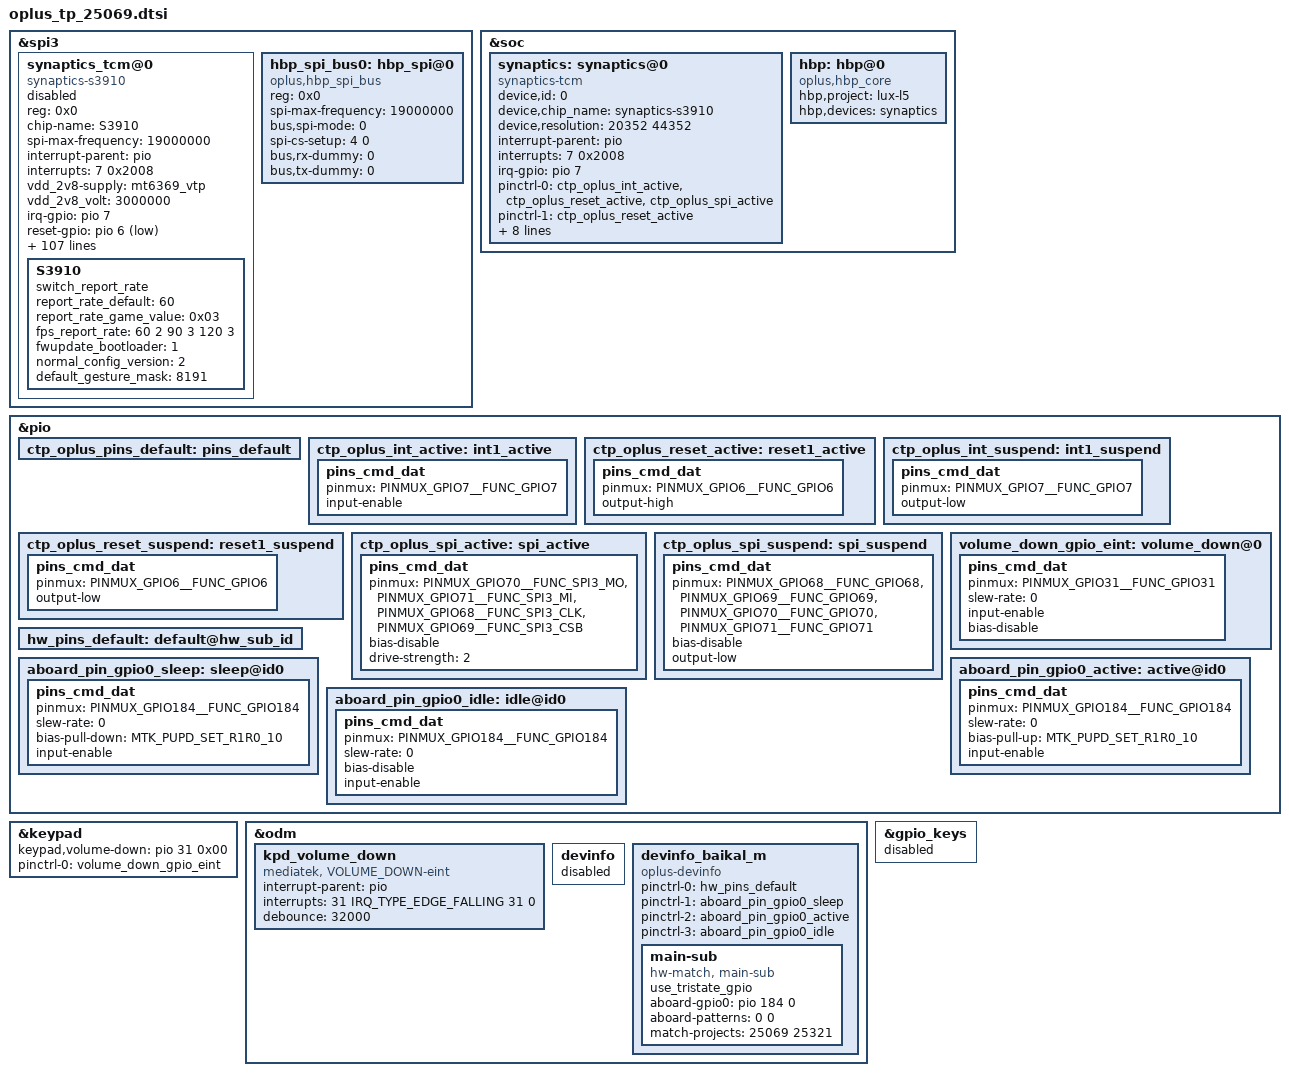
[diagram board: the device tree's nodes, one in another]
&spi3 {
	status = "okay";
	#address-cells = <1>;
	#size-cells = <0>;

	synaptics_tcm@0{
		compatible = "synaptics-s3910";
		reg = <0x0>;
		chip-name = "S3910";
		status = "disable";
		spi-max-frequency = <19000000>;

		/* Interrupt && Irq-gpio */
		interrupt-parent = <&pio>;
		interrupts = <7 0x2008>;

		/* Power Config */
		/* vcc_1v8-supply  = <&mt6369_vant18>; */
		/* vcc_1v8_volt = <1800000>; */
		vdd_2v8-supply  = <&mt6369_vtp>;
		vdd_2v8_volt = <3000000>;

		/* Other HW Resource */
		irq-gpio = <&pio 7 0x2008>;
		reset-gpio = <&pio 6 0x1>;

		pinctrl-names = "default",  "oplus_int_active",
		"oplus_reset_active", "oplus_int_suspend",
		"oplus_reset_suspend", "oplus_spi_active",
		"oplus_spi_suspend";
		pinctrl-0 = <&ctp_oplus_pins_default>;
		pinctrl-1 = <&ctp_oplus_int_active>;
		pinctrl-2 = <&ctp_oplus_reset_active>;
		pinctrl-3 = <&ctp_oplus_int_suspend>;
		pinctrl-4 = <&ctp_oplus_reset_suspend>;
		pinctrl-5 = <&ctp_oplus_spi_active>;
		pinctrl-6 = <&ctp_oplus_spi_suspend>;

		touchpanel,max-num-support = <10>;
		touchpanel,tx-rx-num = <18 39>;
		touchpanel,panel-coords = <20352 44352>;
		touchpanel,display-coords = <1272 2772>;
		touchpanel,touchmajor-limit = <128 216>;
		touchpanel,elimination-range = <20 200 200>;
		touchpanel,int-mode = <1>; /*0: interrupt and disable, 1:interrupt and not disable*/
		touchpanel,smooth-level = <0 1 2 4 7 9>;
		touchpanel,smooth-level-charging = <0 2 4 7 8 9>;
		touchpanel,sensitive-level = <0 70 55 40 25 10>;
		touchpanel,single-optimized-time = <8>;
		touchpanel,high-frame-rate-time = <60>;

		panel_type = <3 7>; /*type:7 TIANMA*/
		platform_support_project = <25069 25321>;
		platform_support_project_dir = <25069 25069>;
		platform_support_project_commandline = "ac382_p_3_a0034_vdo_panel","ac382_p_7_a0034_vdo_panel";


		prevention,curved_screen_V2;
		prevention,grip_disable_level = <6>;
		prevention,updelay_time_ms = <30>;
		prevention,makeup_cnt_weight = <4 1 2 2 2>;
		prevention,large_corner_range = <1380 3400>;
		prevention,large_corner_judge_condition = <500 300 1000 7 7>;
		prevention,trx_reject_condition = <8 7 7>;
		prevention,trx_strict_reject_condition = <8 6 6>;
		prevention,large_judge_time_ms = <500 50 30>;
		prevention,large_exit_condition = <8 8 2>;
		prevention,single_channel_width = <320 320>;
		prevention,normal_tap_condition = <10 350>;
		prevention,long_edge_condition = <179 90 120 80>;
		prevention,long_strict_edge_condition = <160 60>;
		prevention,long_fingerhold_condition = <70 6 4 4>;
		prevention,short_edge_condition = <179 90 120 80>;
		prevention,short_strict_edge_condition = <160 60>;
		prevention,large_strict_exit_condition = <6 6>;
		prevention,top_corner_config = <250 750 1000>;
		prevention,edge_swipe_config = <340 1130>;

		prevention,curved_screen_V4;
		prevention,long_eliminate_point_type = <2 20352 9240 240 44352 300 1>;
		prevention,long_fingerhold_condition2 = <700 2000 0 0>;
		prevention,top_corner_config2 =<3 80 600 1500 0>;
		prevention,hor_long_top_corner_config =<300 2000 0 0>;
		prevention,top_middle_config =<20352 1000 1000 0>;
		prevention,corner_eliminate_point_type =<0 1380 2270 1>;
		prevention,finger_hold_differ_size = <1 0 400 300>;
		prevention,finger_hold_max_rx_exit_distance = <5 350 2300>;
		prevention,max_rx_exit_distance = <1 5 150 350 2000>;
		prevention,dynamic_finger_hold_exit_distance = <1 350 2300 450>;
		prevention,edge_sliding_matched_support = <1 150 3 0>;

		//grip v4.2 reclining mode
		prevention,reclining_mode_support = <1>;
		prevention,long_eliminate_point_type_recli = <2 20352 9240 240 44352 500 1>;
		prevention,finger_hold_differ_size_recli = <1 0 400 400>;
		prevention,finger_hold_max_rx_exit_distance_recli = <5 350 2300>;
		prevention,max_rx_exit_distance_recli = <1 5 100 350 2300>;
		prevention,dynamic_finger_hold_exit_distance_recli = <1 350 2300 450>;
		prevention,edge_sliding_matched_support_recli = <1 150 3 0>;
		prevention,long_edge_condition_recli = <179 90 120 80>;

		/* SW Support Feature Control */
		black_gesture_support;
		sportify_aod_gesture_support;
		pressure_report_support;
		charger_pump_support;
		game_switch_support;
		glove_mode_support;
		smart_gesture_support;
		fw_update_app_support;
		fingerprint_underscreen_support;
		freq_hop_simulate_support;
		report_flow_unlock_support;
		screenoff_fingerprint_info_support;
		irq_need_dev_resume_ok;
		enable_point_auto_change;
		kernel_grip_support;
		//grip_no_driver_support;
		health_monitor_support;
		black_gesture_indep_support;
		snr_read_support;
		palm_to_sleep_support;
		exception_upload_support;
		tp_data_record_support;
		fingerprint_not_report_in_suspend;
		/*
		 *Virtual Key Config:
		 *1:touchpanel,button-type: <virtualkey_type  supportted_button-map>
		 *virtualkey_type:
		 *Type 1: using board_properties
		 *Type 2: using same IC (button zone&& touch zone are seprate)
		 *Type 3: using diffrent IC (button zone&& touch zone are seprate)
		 *Type 4: No need of virtual key process
		 *supportted_button-map:select|menu|home|back
		 *
		 *2:touchpanel,button-map
		 *type (X1,Y1)(X2,Y2)(X3,Y3)(Width_X,Hight_Y)--Only when button-type is 0
		 */
		touchpanel,button-type = <4>;
		touchpanel.button-TRx = <0 0>;

		S3910 {
			switch_report_rate;
			report_rate_default = <60>;
			report_rate_game_value = <0x03>;
			fps_report_rate = <60 2 90 3 120 3>;//1:360Hz 2:125Hz 3:240Hz
			fwupdate_bootloader = <1>;
			normal_config_version = <2>;
			default_gesture_mask = <8191>;
		};
	};
	hbp_spi_bus0:hbp_spi@0 {
		compatible = "oplus,hbp_spi_bus";
		reg = <0x0>;
		status = "okay";


		spi-max-frequency = <19000000>;
		bus,spi-mode = <0>;
		spi-cs-setup = <4 0>;
		bus,rx-dummy = <0>;
		bus,tx-dummy = <0>;
	};
};

&soc {
	synaptics:synaptics@0 {
		compatible = "synaptics-tcm";
		status = "okay";


		device,id = <0>;
		device,chip_name = "synaptics-s3910";
		device,resolution = <20352 44352>;

		/*interrupt config*/
		interrupt-parent = <&pio>;
		interrupts = <7 0x2008>;
		irq-gpio = <&pio 7 0x2008>;

		pinctrl-names = "default",
				"ts_reset_active",
				"ts_reset_idle",
				"ts_resume",
				"ts_suspend";
		pinctrl-0 = <&ctp_oplus_int_active &ctp_oplus_reset_active &ctp_oplus_spi_active>;
		pinctrl-1 = <&ctp_oplus_reset_active>;
		pinctrl-2 = <&ctp_oplus_reset_suspend>;
		pinctrl-3 = <&ctp_oplus_spi_active>;
		pinctrl-4 = <&ctp_oplus_spi_suspend>;

		/*cs active state, not used now*/
		spi,cs_active = <0>;

		/*power config*/
		power,avdd-supply = <&mt6369_vtp>;
		power,avdd_volt = <3000000 3000000>;

		//power,vddi-supply = <&mt6369_vant18>;
		//power,vddi_volt = <1800000 1800000>;

		/*bus config*/
		device,attached_bus = <&hbp_spi_bus0>;

		create_with_power_on_support;
	};

	hbp:hbp@0 {
		compatible = "oplus,hbp_core";
		hbp,project = "lux-l5";
		hbp,devices = <&synaptics>;
	};
};

&pio {
	ctp_oplus_pins_default: pins_default {
	};
	ctp_oplus_int_active: int1_active {
		pins_cmd_dat {
			pinmux = <PINMUX_GPIO7__FUNC_GPIO7>;
			input-enable;
		};
	};
	ctp_oplus_reset_active: reset1_active {
		pins_cmd_dat {
			pinmux = <PINMUX_GPIO6__FUNC_GPIO6>;
			output-high;
		};
	};
	ctp_oplus_int_suspend: int1_suspend {
		pins_cmd_dat {
			pinmux = <PINMUX_GPIO7__FUNC_GPIO7>;
			output-low;
		};
	};
	ctp_oplus_reset_suspend: reset1_suspend {
		pins_cmd_dat {
			pinmux = <PINMUX_GPIO6__FUNC_GPIO6>;
			output-low;
		};
	};
	ctp_oplus_spi_active: spi_active {
		pins_cmd_dat {
			pinmux = <PINMUX_GPIO70__FUNC_SPI3_MO>,
				<PINMUX_GPIO71__FUNC_SPI3_MI>,
				<PINMUX_GPIO68__FUNC_SPI3_CLK>,
				<PINMUX_GPIO69__FUNC_SPI3_CSB>;
			bias-disable;
			drive-strength = <2>;
		};
	};
	ctp_oplus_spi_suspend: spi_suspend {
		pins_cmd_dat {
			pinmux = <PINMUX_GPIO68__FUNC_GPIO68>,
				<PINMUX_GPIO69__FUNC_GPIO69>,
				<PINMUX_GPIO70__FUNC_GPIO70>,
				<PINMUX_GPIO71__FUNC_GPIO71>;
			bias-disable;
			output-low;
		};
	};
};

&keypad {
        keypad,volume-down = <&pio 31 0x00>;
        pinctrl-names = "volume_down_as_int";
        pinctrl-0 = <&volume_down_gpio_eint>;
        status = "okay";
};

&pio {
        volume_down_gpio_eint:volume_down@0{
                pins_cmd_dat {
                        pinmux = <PINMUX_GPIO31__FUNC_GPIO31>;
                        slew-rate = <0>;  /*direction 0:in, 1:out*/
                        input-enable;
                        bias-disable;
                };
        };
};

&odm {
        kpd_volume_down:kpd_volume_down {
                compatible = "mediatek, VOLUME_DOWN-eint";
                interrupt-parent = <&pio>;
                interrupts = <31 IRQ_TYPE_EDGE_FALLING 31 0>;
                debounce = <32000>;
                status = "okay";
        };
};

&odm {
	devinfo {
		status = "disabled";
	};

	devinfo_baikal_m {
		compatible = "oplus-devinfo";

		pinctrl-names = "default", "aboard_gpio0_sleep", "aboard_gpio0_active", "aboard_gpio0_idle";
		pinctrl-0 = <&hw_pins_default>;
		pinctrl-1 = <&aboard_pin_gpio0_sleep>;
		pinctrl-2 = <&aboard_pin_gpio0_active>;
		pinctrl-3 = <&aboard_pin_gpio0_idle>;

		main-sub {
			compatible = "hw-match, main-sub";
			use_tristate_gpio;
			aboard-gpio0 = <&pio 184 0>;
			aboard-patterns = <0 0>;	/*0[high-resistance] 1[pull-down] 2[pull-up]*/
			/*main board*/
			match-projects = <25069 25321>;
		};
	};
};

&pio{
	hw_pins_default:default@hw_sub_id {
	};

	aboard_pin_gpio0_sleep:sleep@id0 {
		pins_cmd_dat {
			pinmux = <PINMUX_GPIO184__FUNC_GPIO184>;
			slew-rate = <0>;
			bias-pull-down = <MTK_PUPD_SET_R1R0_10>;
			input-enable;
		};
	};

	aboard_pin_gpio0_active:active@id0 {
		pins_cmd_dat {
			pinmux = <PINMUX_GPIO184__FUNC_GPIO184>;
			slew-rate = <0>;
			bias-pull-up = <MTK_PUPD_SET_R1R0_10>;
			input-enable;
		};
	};

	aboard_pin_gpio0_idle:idle@id0 {
		pins_cmd_dat {
			pinmux = <PINMUX_GPIO184__FUNC_GPIO184>;
			slew-rate = <0>;
			bias-disable;
			input-enable;
		};
	};
};

&gpio_keys {
	status = "disabled";
};
